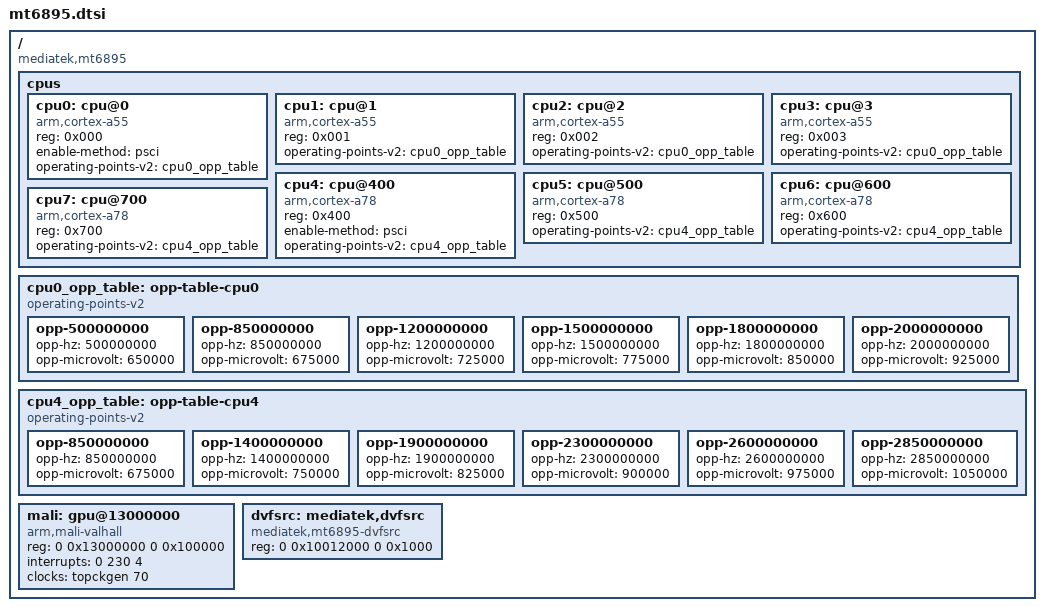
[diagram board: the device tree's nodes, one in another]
// SPDX-License-Identifier: GPL-2.0
/*
 * MediaTek MT6895 (Dimensity 8100 / 8200) Device Tree Source
 * Reference: Poco X4 GT / Redmi K50 (Matisse / Rubens)
 * Source: MiCode/Xiaomi_Kernel_OpenSource (matisse-s-oss)
 */

/ {
	compatible = "mediatek,mt6895";
	#address-cells = <2>;
	#size-cells = <2>;

	cpus {
		#address-cells = <1>;
		#size-cells = <0>;

		/* Little Cluster (Cores 0-3): 4x Cortex-A55 up to 2.0 GHz */
		cpu0: cpu@0 {
			device_type = "cpu";
			compatible = "arm,cortex-a55";
			reg = <0x000>;
			enable-method = "psci";
			operating-points-v2 = <&cpu0_opp_table>;
		};
		cpu1: cpu@1 {
			device_type = "cpu";
			compatible = "arm,cortex-a55";
			reg = <0x001>;
			operating-points-v2 = <&cpu0_opp_table>;
		};
		cpu2: cpu@2 {
			device_type = "cpu";
			compatible = "arm,cortex-a55";
			reg = <0x002>;
			operating-points-v2 = <&cpu0_opp_table>;
		};
		cpu3: cpu@3 {
			device_type = "cpu";
			compatible = "arm,cortex-a55";
			reg = <0x003>;
			operating-points-v2 = <&cpu0_opp_table>;
		};

		/* Big Cluster (Cores 4-7): 4x Cortex-A78 up to 2.85 GHz */
		cpu4: cpu@400 {
			device_type = "cpu";
			compatible = "arm,cortex-a78";
			reg = <0x400>;
			enable-method = "psci";
			operating-points-v2 = <&cpu4_opp_table>;
		};
		cpu5: cpu@500 {
			device_type = "cpu";
			compatible = "arm,cortex-a78";
			reg = <0x500>;
			operating-points-v2 = <&cpu4_opp_table>;
		};
		cpu6: cpu@600 {
			device_type = "cpu";
			compatible = "arm,cortex-a78";
			reg = <0x600>;
			operating-points-v2 = <&cpu4_opp_table>;
		};
		cpu7: cpu@700 {
			device_type = "cpu";
			compatible = "arm,cortex-a78";
			reg = <0x700>;
			operating-points-v2 = <&cpu4_opp_table>;
		};
	};

	cpu0_opp_table: opp-table-cpu0 {
		compatible = "operating-points-v2";
		opp-500000000  { opp-hz = /bits/ 64 <500000000>;  opp-microvolt = <650000>; };
		opp-850000000  { opp-hz = /bits/ 64 <850000000>;  opp-microvolt = <675000>; };
		opp-1200000000 { opp-hz = /bits/ 64 <1200000000>; opp-microvolt = <725000>; };
		opp-1500000000 { opp-hz = /bits/ 64 <1500000000>; opp-microvolt = <775000>; };
		opp-1800000000 { opp-hz = /bits/ 64 <1800000000>; opp-microvolt = <850000>; };
		opp-2000000000 { opp-hz = /bits/ 64 <2000000000>; opp-microvolt = <925000>; };
	};

	cpu4_opp_table: opp-table-cpu4 {
		compatible = "operating-points-v2";
		opp-850000000  { opp-hz = /bits/ 64 <850000000>;  opp-microvolt = <675000>; };
		opp-1400000000 { opp-hz = /bits/ 64 <1400000000>; opp-microvolt = <750000>; };
		opp-1900000000 { opp-hz = /bits/ 64 <1900000000>; opp-microvolt = <825000>; };
		opp-2300000000 { opp-hz = /bits/ 64 <2300000000>; opp-microvolt = <900000>; };
		opp-2600000000 { opp-hz = /bits/ 64 <2600000000>; opp-microvolt = <975000>; };
		opp-2850000000 { opp-hz = /bits/ 64 <2850000000>; opp-microvolt = <1050000>; };
	};

	/* ARM Mali-G610 MC6 (Valhall v3) */
	mali: gpu@13000000 {
		compatible = "arm,mali-valhall", "arm,mali-g610";
		reg = <0 0x13000000 0 0x100000>;
		interrupts = <0 230 4>;
		clocks = <&topckgen 70>;
		clock-names = "mali_core";
	};

	/* MediaTek DVFSRC & HyperEngine Framework */
	dvfsrc: mediatek,dvfsrc {
		compatible = "mediatek,mt6895-dvfsrc";
		reg = <0 0x10012000 0 0x1000>;
	};
};
